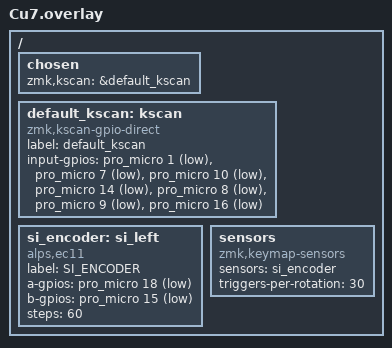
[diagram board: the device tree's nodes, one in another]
/ {
    chosen {
        zmk,kscan = &default_kscan;
    };

    default_kscan: kscan {
        compatible = "zmk,kscan-gpio-direct";
        label = "default_kscan";

       input-gpios = 
         <&pro_micro 1 (GPIO_ACTIVE_LOW | GPIO_PULL_UP)>,
         <&pro_micro 7 (GPIO_ACTIVE_LOW | GPIO_PULL_UP)>,
         <&pro_micro 10 (GPIO_ACTIVE_LOW | GPIO_PULL_UP)>,
         <&pro_micro 14 (GPIO_ACTIVE_LOW | GPIO_PULL_UP)>,
         <&pro_micro 8 (GPIO_ACTIVE_LOW | GPIO_PULL_UP)>,
         <&pro_micro 9 (GPIO_ACTIVE_LOW | GPIO_PULL_UP)>,
         <&pro_micro 16 (GPIO_ACTIVE_LOW | GPIO_PULL_UP)>;
    };

si_encoder: si_left {
        compatible = "alps,ec11";
        label = "SI_ENCODER";
        a-gpios = <&pro_micro 18 (GPIO_ACTIVE_LOW | GPIO_PULL_UP)>;
        b-gpios = <&pro_micro 15 (GPIO_ACTIVE_LOW | GPIO_PULL_UP)>;
        steps = <60>;
    };

sensors {
        compatible = "zmk,keymap-sensors";
        sensors = <&si_encoder>;
        triggers-per-rotation = <30>;
    };
};
